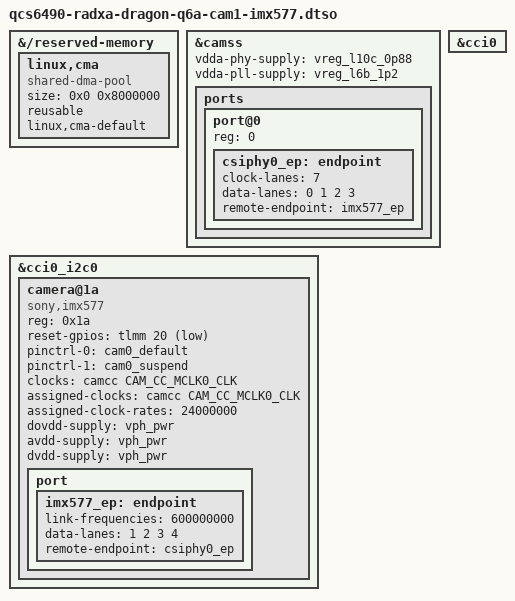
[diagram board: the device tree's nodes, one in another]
// SPDX-License-Identifier: BSD-3-Clause
/*
 * Copyright (c) 2025 Radxa Computer (Shenzhen) Co., Ltd.
 */

/dts-v1/;
/plugin/;

#include <dt-bindings/clock/qcom,camcc-sc7280.h>
#include <dt-bindings/gpio/gpio.h>

&{/reserved-memory} {
	linux,cma {
		compatible = "shared-dma-pool";
		size = <0x0 0x8000000>;
		reusable;
		linux,cma-default;
	};
};

&camss {
	vdda-phy-supply = <&vreg_l10c_0p88>;
	vdda-pll-supply = <&vreg_l6b_1p2>;

	status = "okay";

	ports {
		#address-cells = <1>;
		#size-cells = <0>;

		/* The port index denotes CSIPHY id i.e. csiphy0 */
		port@0 {
			reg = <0>;

			csiphy0_ep: endpoint {
				clock-lanes = <7>;
				data-lanes = <0 1 2 3>;
				remote-endpoint = <&imx577_ep>;
			};
		};
	};
};

&cci0 {
	status = "okay";
};

&cci0_i2c0 {
	#address-cells = <1>;
	#size-cells = <0>;

	camera@1a {
		compatible = "sony,imx577";

		reg = <0x1a>;

		reset-gpios = <&tlmm 20 GPIO_ACTIVE_LOW>;
		pinctrl-names = "default", "suspend";
		pinctrl-0 = <&cam0_default>;
		pinctrl-1 = <&cam0_suspend>;

		clocks = <&camcc CAM_CC_MCLK0_CLK>;
		assigned-clocks = <&camcc CAM_CC_MCLK0_CLK>;
		assigned-clock-rates = <24000000>;

		dovdd-supply = <&vph_pwr>;
		avdd-supply = <&vph_pwr>;
		dvdd-supply = <&vph_pwr>;

		port {
			imx577_ep: endpoint {
				link-frequencies = /bits/ 64 <600000000>;
				data-lanes = <1 2 3 4>;
				remote-endpoint = <&csiphy0_ep>;
			};
		};
	};
};
